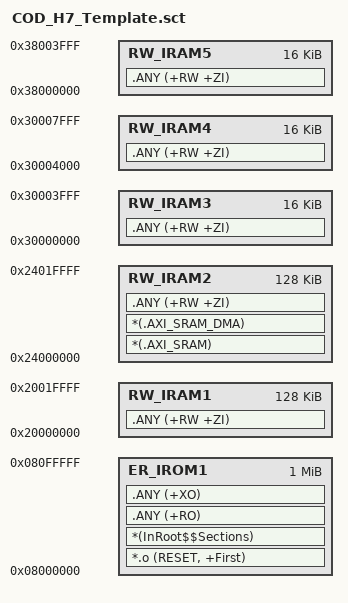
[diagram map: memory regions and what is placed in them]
; *****************************************************************************
; *** S27_TEST_2 - hand written scatter file (not generated by uVision)     ***
; *** Keep in sync with project.uvprojx: IROM1 0x08000000 size 0x00100000.  ***
; *** This file is ignored by .gitignore (*.sct); an exception was added.   ***
; *****************************************************************************

LR_IROM1 0x08000000 0x00100000  {    ; load region size_region
  ER_IROM1 0x08000000 0x00100000  {  ; load address = execution address
   *.o (RESET, +First)
   *(InRoot$$Sections)
   .ANY (+RO)
   .ANY (+XO)
  }
  ; ---- DTCM 128 KiB: main RAM (NOT accessible by DMA1/DMA2, do not place DMA buffers here) ----
  RW_IRAM1 0x20000000 0x00020000  {
   .ANY (+RW +ZI)
  }
  ; ---- AXI SRAM 128 KiB: DMA buffers with explicit section placement (32-byte aligned) ----
  RW_IRAM2 0x24000000 0x00020000  {
   *(.AXI_SRAM)
   *(.AXI_SRAM_DMA)  ; DMA缓冲区的显式section，保证对齐和位置
   .ANY (+RW +ZI)
  }
  ; ---- spare SRAM windows: kept so the map stays stable ----
  RW_IRAM3 0x30000000 0x00004000  {
   .ANY (+RW +ZI)
  }
  RW_IRAM4 0x30004000 0x00004000  {
   .ANY (+RW +ZI)
  }
  RW_IRAM5 0x38000000 0x00004000  {
   .ANY (+RW +ZI)
  }
}
